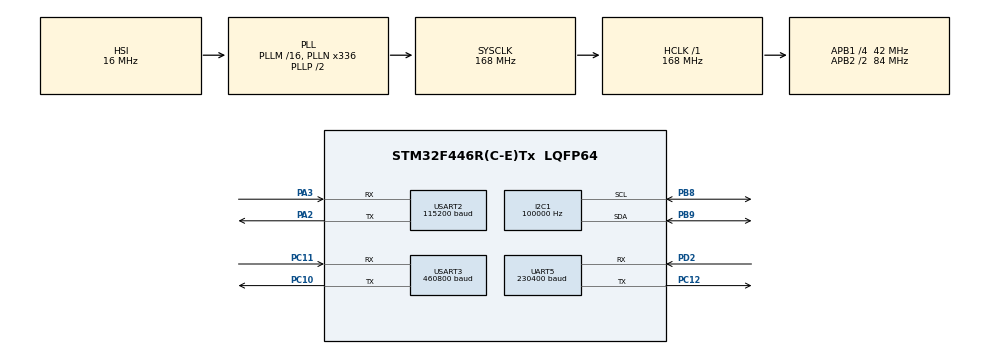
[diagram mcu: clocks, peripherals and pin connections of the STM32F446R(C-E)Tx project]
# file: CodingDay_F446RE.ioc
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Dma.Request0=USART3_RX
Dma.USART3_RX.0.Direction=DMA_PERIPH_TO_MEMORY
Dma.USART3_RX.0.FIFOMode=DMA_FIFOMODE_DISABLE
Dma.USART3_RX.0.Instance=DMA1_Stream1
Dma.USART3_RX.0.MemDataAlignment=DMA_MDATAALIGN_BYTE
Dma.USART3_RX.0.MemInc=DMA_MINC_ENABLE
Dma.USART3_RX.0.Mode=DMA_CIRCULAR
Dma.USART3_RX.0.PeriphDataAlignment=DMA_PDATAALIGN_BYTE
Dma.USART3_RX.0.PeriphInc=DMA_PINC_DISABLE
Dma.USART3_RX.0.Priority=DMA_PRIORITY_HIGH
I2C1.ClockSpeed=100000
Mcu.Family=STM32F4
Mcu.Name=STM32F446R(C-E)Tx
Mcu.Package=LQFP64
NVIC.DMA1_Stream1_IRQn=true\:0\:0\:false\:false\:true\:true\:true\:true
NVIC.I2C1_ER_IRQn=true\:1\:0\:false\:false\:true\:true\:true\:true
NVIC.I2C1_EV_IRQn=true\:1\:0\:false\:false\:true\:true\:true\:true
NVIC.PriorityGroup=NVIC_PRIORITYGROUP_4
NVIC.TIM6_DAC_IRQn=true\:0\:0\:false\:false\:true\:true\:true\:true
NVIC.UART5_IRQn=true\:0\:0\:false\:false\:true\:true\:true\:true
NVIC.USART2_IRQn=true\:0\:0\:false\:false\:true\:true\:true\:true
NVIC.USART3_IRQn=true\:0\:0\:false\:false\:true\:true\:true\:true
PA13.Mode=Serial_Wire
PA13.Signal=SYS_JTMS-SWDIO
PA14.Mode=Serial_Wire
PA14.Signal=SYS_JTCK-SWCLK
PA2.Mode=Asynchronous
PA2.Signal=USART2_TX
PA3.Mode=Asynchronous
PA3.Signal=USART2_RX
PB8.Mode=I2C
PB8.Signal=I2C1_SCL
PB9.Mode=I2C
PB9.Signal=I2C1_SDA
PC10.Mode=Asynchronous
PC10.Signal=USART3_TX
PC11.Mode=Asynchronous
PC11.Signal=USART3_RX
PC12.Mode=Asynchronous
PC12.Signal=UART5_TX
PD2.Mode=Asynchronous
PD2.Signal=UART5_RX
ProjectManager.HeapSize=0x200
ProjectManager.StackSize=0x400
ProjectManager.TargetToolchain=STM32CubeIDE
RCC.AHBCLKDivider=RCC_SYSCLK_DIV1
RCC.AHBFreq_Value=168000000
RCC.APB1CLKDivider=RCC_HCLK_DIV4
RCC.APB1Freq_Value=42000000
RCC.APB1TimFreq_Value=84000000
RCC.APB2CLKDivider=RCC_HCLK_DIV2
RCC.APB2Freq_Value=84000000
RCC.APB2TimFreq_Value=168000000
RCC.CortexFreq_Value=168000000
RCC.HCLKFreq_Value=168000000
RCC.PLLM=16
RCC.PLLN=336
RCC.PLLP=RCC_PLLP_DIV2
RCC.PLLQ=7
RCC.PLLSourceVirtual=RCC_PLLSOURCE_HSI
RCC.SYSCLKFreq_VALUE=168000000
RCC.SYSCLKSource=RCC_SYSCLKSOURCE_PLLCLK
RCC.USBFreq_Value=48000000
RCC.VCOOutputFreq_Value=336000000
TIM6.Period=99
TIM6.Prescaler=8399
UART5.BaudRate=230400
UART5.VirtualMode=Asynchronous
USART2.BaudRate=115200
USART2.VirtualMode=VM_ASYNC
USART3.BaudRate=460800
USART3.VirtualMode=VM_ASYNC
VP_TIM6_VS_ClockSourceINT.Mode=Enable_Timer
board=custom

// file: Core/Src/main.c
/* USER CODE BEGIN Header */
/**
  ******************************************************************************
  * @file           : main.c
  * @brief          : Main program body
  ******************************************************************************
  * @attention
  *
  * Copyright (c) 2026 STMicroelectronics.
  * All rights reserved.
  *
  * This software is licensed under terms that can be found in the LICENSE file
  * in the root directory of this software component.
  * If no LICENSE file comes with this software, it is provided AS-IS.
  *
  ******************************************************************************
  */
/* USER CODE END Header */
#include "main.h"

/* USER CODE BEGIN Includes */
#include "app.h"
#include "app_rtos.h"
/* USER CODE END Includes */

I2C_HandleTypeDef hi2c1;

TIM_HandleTypeDef htim6;

UART_HandleTypeDef huart5;
UART_HandleTypeDef huart2;
UART_HandleTypeDef huart3;
DMA_HandleTypeDef hdma_usart3_rx;

void SystemClock_Config(void);
static void MX_GPIO_Init(void);
static void MX_DMA_Init(void);
static void MX_I2C1_Init(void);
static void MX_TIM6_Init(void);
static void MX_UART5_Init(void);
static void MX_USART2_UART_Init(void);
static void MX_USART3_UART_Init(void);

int main(void)
{

  /* MCU Configuration--------------------------------------------------------*/

  /* Reset of all peripherals, Initializes the Flash interface and the Systick. */
  HAL_Init();

  /* Configure the system clock */
  SystemClock_Config();

  /* Initialize all configured peripherals */
  MX_GPIO_Init();
  MX_DMA_Init();
  MX_I2C1_Init();
  MX_TIM6_Init();
  MX_UART5_Init();
  MX_USART2_UART_Init();
  MX_USART3_UART_Init();
  /* USER CODE BEGIN 2 */
  app_init();
  /* USER CODE END 2 */

  /* Infinite loop */
  while (1)
  {

    /* USER CODE BEGIN 3 */
    /* Hands control to the FreeRTOS scheduler.  osKernelStart() never returns:
     * from now on everything runs inside the LiDAR Parser Task and the
     * Output/Debug Task. */
    app_rtos_start();
  }
  /* USER CODE END 3 */
}

void SystemClock_Config(void)
{
  RCC_OscInitTypeDef RCC_OscInitStruct = {0};
  RCC_ClkInitTypeDef RCC_ClkInitStruct = {0};

  /** Configure the main internal regulator output voltage
  */
  __HAL_RCC_PWR_CLK_ENABLE();
  __HAL_PWR_VOLTAGESCALING_CONFIG(PWR_REGULATOR_VOLTAGE_SCALE1);

  /** Initializes the RCC Oscillators according to the specified parameters
  * in the RCC_OscInitTypeDef structure.
  */
  RCC_OscInitStruct.OscillatorType = RCC_OSCILLATORTYPE_HSI;
  RCC_OscInitStruct.HSIState = RCC_HSI_ON;
  RCC_OscInitStruct.HSICalibrationValue = RCC_HSICALIBRATION_DEFAULT;
  RCC_OscInitStruct.PLL.PLLState = RCC_PLL_ON;
  RCC_OscInitStruct.PLL.PLLSource = RCC_PLLSOURCE_HSI;
  RCC_OscInitStruct.PLL.PLLM = 16;
  RCC_OscInitStruct.PLL.PLLN = 336;
  RCC_OscInitStruct.PLL.PLLP = RCC_PLLP_DIV2;
  RCC_OscInitStruct.PLL.PLLQ = 7;
  RCC_OscInitStruct.PLL.PLLR = 2;
  if (HAL_RCC_OscConfig(&RCC_OscInitStruct) != HAL_OK)
  {
    Error_Handler();
  }

  /** Initializes the CPU, AHB and APB buses clocks
  */
  RCC_ClkInitStruct.ClockType = RCC_CLOCKTYPE_HCLK|RCC_CLOCKTYPE_SYSCLK
                              |RCC_CLOCKTYPE_PCLK1|RCC_CLOCKTYPE_PCLK2;
  RCC_ClkInitStruct.SYSCLKSource = RCC_SYSCLKSOURCE_PLLCLK;
  RCC_ClkInitStruct.AHBCLKDivider = RCC_SYSCLK_DIV1;
  RCC_ClkInitStruct.APB1CLKDivider = RCC_HCLK_DIV4;
  RCC_ClkInitStruct.APB2CLKDivider = RCC_HCLK_DIV2;

  if (HAL_RCC_ClockConfig(&RCC_ClkInitStruct, FLASH_LATENCY_5) != HAL_OK)
  {
    Error_Handler();
  }
}

static void MX_I2C1_Init(void)
{

  hi2c1.Instance = I2C1;
  hi2c1.Init.ClockSpeed = 100000;
  hi2c1.Init.DutyCycle = I2C_DUTYCYCLE_2;
  hi2c1.Init.OwnAddress1 = 0;
  hi2c1.Init.AddressingMode = I2C_ADDRESSINGMODE_7BIT;
  hi2c1.Init.DualAddressMode = I2C_DUALADDRESS_DISABLE;
  hi2c1.Init.OwnAddress2 = 0;
  hi2c1.Init.GeneralCallMode = I2C_GENERALCALL_DISABLE;
  hi2c1.Init.NoStretchMode = I2C_NOSTRETCH_DISABLE;
  if (HAL_I2C_Init(&hi2c1) != HAL_OK)
  {
    Error_Handler();
  }

}

static void MX_TIM6_Init(void)
{

  TIM_MasterConfigTypeDef sMasterConfig = {0};

  htim6.Instance = TIM6;
  htim6.Init.Prescaler = 8399;
  htim6.Init.CounterMode = TIM_COUNTERMODE_UP;
  htim6.Init.Period = 99;
  htim6.Init.AutoReloadPreload = TIM_AUTORELOAD_PRELOAD_DISABLE;
  if (HAL_TIM_Base_Init(&htim6) != HAL_OK)
  {
    Error_Handler();
  }
  sMasterConfig.MasterOutputTrigger = TIM_TRGO_RESET;
  sMasterConfig.MasterSlaveMode = TIM_MASTERSLAVEMODE_DISABLE;
  if (HAL_TIMEx_MasterConfigSynchronization(&htim6, &sMasterConfig) != HAL_OK)
  {
    Error_Handler();
  }

}

static void MX_UART5_Init(void)
{

  huart5.Instance = UART5;
  huart5.Init.BaudRate = 230400;
  huart5.Init.WordLength = UART_WORDLENGTH_8B;
  huart5.Init.StopBits = UART_STOPBITS_1;
  huart5.Init.Parity = UART_PARITY_NONE;
  huart5.Init.Mode = UART_MODE_TX_RX;
  huart5.Init.HwFlowCtl = UART_HWCONTROL_NONE;
  huart5.Init.OverSampling = UART_OVERSAMPLING_16;
  if (HAL_UART_Init(&huart5) != HAL_OK)
  {
    Error_Handler();
  }

}

static void MX_USART2_UART_Init(void)
{

  huart2.Instance = USART2;
  huart2.Init.BaudRate = 115200;
  huart2.Init.WordLength = UART_WORDLENGTH_8B;
  huart2.Init.StopBits = UART_STOPBITS_1;
  huart2.Init.Parity = UART_PARITY_NONE;
  huart2.Init.Mode = UART_MODE_TX_RX;
  huart2.Init.HwFlowCtl = UART_HWCONTROL_NONE;
  huart2.Init.OverSampling = UART_OVERSAMPLING_16;
  if (HAL_UART_Init(&huart2) != HAL_OK)
  {
    Error_Handler();
  }

}

static void MX_USART3_UART_Init(void)
{

  huart3.Instance = USART3;
  huart3.Init.BaudRate = 460800;
  huart3.Init.WordLength = UART_WORDLENGTH_8B;
  huart3.Init.StopBits = UART_STOPBITS_1;
  huart3.Init.Parity = UART_PARITY_NONE;
  huart3.Init.Mode = UART_MODE_TX_RX;
  huart3.Init.HwFlowCtl = UART_HWCONTROL_NONE;
  huart3.Init.OverSampling = UART_OVERSAMPLING_16;
  if (HAL_UART_Init(&huart3) != HAL_OK)
  {
    Error_Handler();
  }

}

static void MX_DMA_Init(void)
{

  /* DMA controller clock enable */
  __HAL_RCC_DMA1_CLK_ENABLE();

  /* DMA interrupt init */
  /* DMA1_Stream1_IRQn interrupt configuration */
  /* NOTE: must stay numerically >= configLIBRARY_MAX_SYSCALL_INTERRUPT_PRIORITY
   * (5) because the LiDAR half/full-complete ISR posts into FreeRTOS Queue 1.
   * app_init() re-applies the same value; it is set here as well so that a
   * CubeMX regeneration cannot silently re-break it. */
  HAL_NVIC_SetPriority(DMA1_Stream1_IRQn, 5, 0);
  HAL_NVIC_EnableIRQ(DMA1_Stream1_IRQn);

}

static void MX_GPIO_Init(void)
{

  /* GPIO Ports Clock Enable */
  __HAL_RCC_GPIOA_CLK_ENABLE();
  __HAL_RCC_GPIOC_CLK_ENABLE();
  __HAL_RCC_GPIOD_CLK_ENABLE();
  __HAL_RCC_GPIOB_CLK_ENABLE();

}

void Error_Handler(void)
{
  __disable_irq();
  while (1)
  {
  }
}
